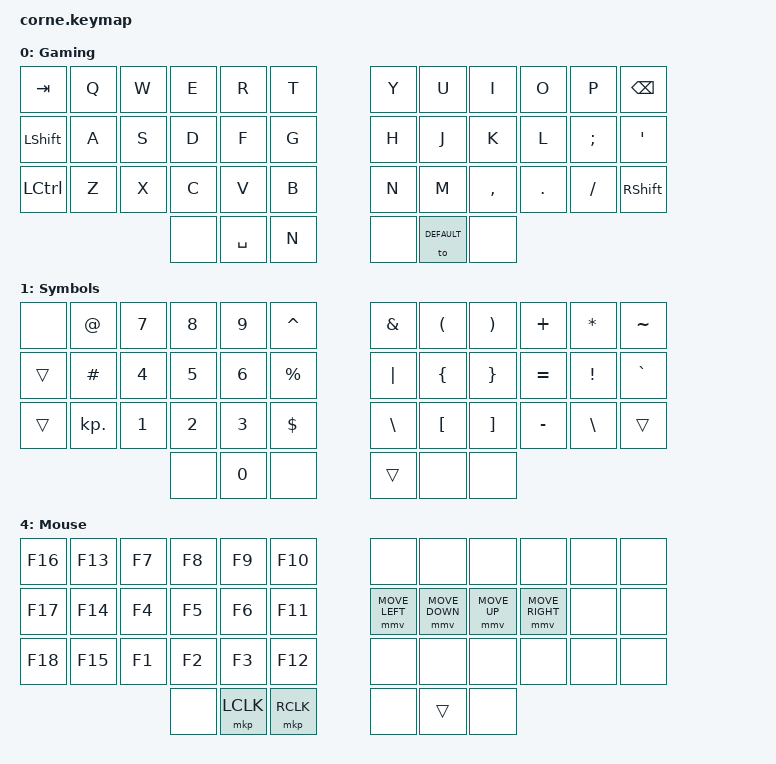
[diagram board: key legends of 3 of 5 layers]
#include <behaviors.dtsi>
#include <dt-bindings/zmk/bt.h>
#include <dt-bindings/zmk/keys.h>

#define DEFAULT 0
#define SYMBOLS 1
#define ACTIONS 2
#define CODING 3
#define MOUSE 4
#define GAMING 5

/ {
    /*
    behaviors {
        hm: homerow_mods {
            compatible = "zmk,behavior-hold-tap";
            label = "HOMEROW_MODS";
            #binding-cells = <2>;
            tapping-term-ms = <200>;
            quick_tap_ms = <0>;
            flavor = "tap-preferred";
            bindings = <&kp>, <&kp>;

            quick-tap-ms = <180>;
            global-quick-tap;
        };

        para: para {
            compatible = "zmk,behavior-tap-dance";
            label = "PARA";
            #binding-cells = <0>;
            bindings = <&kp LEFT_PARENTHESIS>, <&kp RIGHT_PARENTHESIS>;
        };

        caps: caps {
            compatible = "zmk,behavior-caps-word";
            label = "CAPS";
            #binding-cells = <0>;
            continue-list = <MINUS BACKSPACE>;
        };

        paraless: paraless {
            compatible = "zmk,behavior-mod-morph";
            label = "PARALESS";
            bindings = <&kp LEFT_PARENTHESIS>, <&kp LESS_THAN>;

            #binding-cells = <0>;
            mods = <(MOD_LSFT)>;
        };

        paragreat: paragreat {
            compatible = "zmk,behavior-mod-morph";
            label = "PARAGREAT";
            bindings = <&kp RIGHT_PARENTHESIS>, <&kp GREATER_THAN>;

            #binding-cells = <0>;
            mods = <(MOD_LSFT)>;
        };
    };

    macros {
        browsertab: browsertab {
            compatible = "zmk,behavior-macro";
            #binding-cells = <0>;
            bindings =
                <&macro_press>,
                <&kp LCTRL>,
                <&macro_tap>,
                <&kp TAB>,
                <&macro_release>,
                <&kp LCTRL>;
        };

    };

    combos {
        compatible = "zmk,combos";

        escape {
            bindings = <&kp ESCAPE>;
            key-positions = <13 29>;
        };

        delete {
            bindings = <&kp DELETE>;
            key-positions = <15 21>;
        };

        perc {
            bindings = <&kp PERCENT>;
            key-positions = <5 17>;
        };

        equal {
            bindings = <&kp EQUAL>;
            key-positions = <28 16>;
        };

        dollar {
            bindings = <&kp DOLLAR>;
            key-positions = <4 16>;
        };

        pound {
            bindings = <&kp POUND>;
            key-positions = <3 15>;
        };

        at {
            bindings = <&kp AT>;
            key-positions = <2 14>;
        };

        backslash {
            bindings = <&kp BACKSLASH>;
            key-positions = <26 14>;
        };

        copy {
            bindings = <&kp K_COPY>;
            key-positions = <28 27>;
        };

        paste {
            bindings = <&kp K_PASTE>;
            key-positions = <26 27>;
        };

        star {
            bindings = <&kp STAR>;
            key-positions = <8 20>;
        };

        slash {
            bindings = <&kp SLASH>;
            key-positions = <32 20>;
        };

        plus {
            bindings = <&kp PLUS>;
            key-positions = <7 19>;
        };

        minus {
            bindings = <&kp KP_MINUS>;
            key-positions = <31 19>;
        };

        underscore {
            bindings = <&kp UNDER>;
            key-positions = <30 18>;
        };

        leftbrack {
            bindings = <&kp LEFT_BRACKET>;
            key-positions = <31 32>;
        };

        rightbrack {
            bindings = <&kp RIGHT_BRACKET>;
            key-positions = <33 32>;
        };

        para-less {
            bindings = <&paraless>;
            key-positions = <20 19>;
        };

        para-great {
            bindings = <&paragreat>;
            key-positions = <20 21>;
        };
    };
    */

    keymap {
        compatible = "zmk,keymap";

        // -----------------------------------------------------------------------------------------

        DEFAULT {
            display-name = "Base";
            bindings = <
                &gresc         &kp Q       &kp W       &kp E        &kp R         &kp T    /*|*/    &kp Y  &kp U         &kp I        &kp O       &kp P          &kp BACKSPACE
                &mt LSHFT TAB  &mt LGUI A  &mt LALT S  &mt LCTRL D  &mt LSHIFT F  &kp G    /*|*/    &kp H  &mt RSHIFT J  &mt RCTRL K  &mt RALT L  &mt RGUI SEMI  &kp SQT
                &mo SYMBOLS    &kp Z       &kp X       &kp C        &kp V         &kp B    /*|*/    &kp N  &kp M         &kp COMMA    &kp DOT     &kp SLASH      &lt SYMBOLS MINUS
                                                        &kp LGUI  &mo ACTIONS  &mo CODING  /*|*/  &kp RET  &lt MOUSE SPACE  &kp LEFT_ALT
            >;
        };

        // -----------------------------------------------------------------------------------------

        SYMBOLS {
            display-name = "Symbols";
            bindings = <
                &none   &kp AT       &kp 7  &kp 8  &kp 9  &kp CARET    /*|*/    &kp AMPS       &kp LPAR  &kp RPAR  &kp PLUS   &kp STAR  &kp TILDE
                &trans  &kp HASH     &kp 4  &kp 5  &kp 6  &kp PERCENT  /*|*/    &kp PIPE       &kp LBRC  &kp RBRC  &kp EQUAL  &kp EXCL  &kp GRAVE
                &trans  &kp KP_DOT   &kp 1  &kp 2  &kp 3  &kp DOLLAR   /*|*/    &kp BACKSLASH  &kp LBKT  &kp RBKT  &kp MINUS  &kp BSLH  &trans
                                                  &none  &kp 0  &none  /*|*/  &trans  &none  &none
            >;
        };

        // -----------------------------------------------------------------------------------------

        ACTIONS {
            display-name = "Actions";
            bindings = <
                &kp C_VOL_UP  &kp C_PREV     &kp C_PP      &kp C_NEXT      &kp LALT SPACE  &kp LGUI DOT   /*|*/   &kp HOME              &kp PG_DN  &kp N8  &kp N9         &none  &kp DEL
                &kp C_MUTE    &kp LGUI       &kp LALT      &kp LCTRL       &kp LSHIFT      &to GAMING     /*|*/   &kp LEFT              &kp DOWN   &kp UP  &kp RIGHT      &none  &kp LGUI LSHIFT S
                &kp C_VOL_DN  &kp C_AC_UNDO  &kp C_AC_CUT  &kp C_AC_COPY   &kp C_AC_PASTE  &none          /*|*/   &kp LCTRL LSHIFT TAB  &none      &none   &kp LCTRL TAB  &none  &none
                                                                                   &none  &trans  &none   /*|*/      &none  &none  &none
            >;
        };

        // -----------------------------------------------------------------------------------------

        CODING {
            display-name = "Coding";
            bindings = <
                &none  &kp LSHFIT F11  &kp F11              &kp F10             &kp F2              &none                /*|*/   &none  &none  &none  &none  &none  &none
                &none  &kp LALT 0      &kp LALT LSHIFT F12  &kp LCTRL P         &kp LALT LSHIFT F   &kp F12              /*|*/   &none  &none  &none  &none  &none  &none
                &none  &none           &none                &kp LALT LSHIFT F8  &kp LALT F8         &kp LCTRL LSHIFT B   /*|*/   &none  &none  &none  &none  &none  &none
                                                                                                  &none  &none  &trans   /*|*/   &kp LCTRL DOT  &none  &none
            >;
        };

        // -----------------------------------------------------------------------------------------

        MOUSE {
            display-name = "Mouse";
            bindings = <
                &kp F16  &kp F13  &kp F7  &kp F8  &kp F9  &kp F10  /*|*/  &none  &none  &none  &none  &none  &none
                &kp F17  &kp F14  &kp F4  &kp F5  &kp F6  &kp F11  /*|*/  &mmv MOVE_LEFT  &mmv MOVE_DOWN  &mmv MOVE_UP  &mmv MOVE_RIGHT  &none  &none
                &kp F18  &kp F15  &kp F1  &kp F2  &kp F3  &kp F12  /*|*/  &none  &none  &none  &none  &none  &none
                                      &none  &mkp LCLK  &mkp RCLK  /*|*/  &none  &trans  &none
            >;
        };

        // -----------------------------------------------------------------------------------------

        DEFAULT {
            display-name = "Gaming";
            bindings = <
&kp TAB    &kp Q  &kp W  &kp E     &kp R  &kp T        &kp Y    &kp U      &kp I          &kp O    &kp P     &kp BACKSPACE
&kp LSHFT  &kp A  &kp S  &kp D     &kp F  &kp G        &kp H    &kp J      &kp K          &kp L    &kp SEMI  &kp SQT
&kp LCTRL  &kp Z  &kp X  &kp C     &kp V  &kp B        &kp N    &kp M      &kp COMMA      &kp DOT  &kp FSLH  &kp RSHFT
                         &none  &kp SPACE  &kp N    &none  &to DEFAULT  &none
            >;
        };
    };

    /*
    conditional_layers {
        compatible = "zmk,conditional-layers";

        l3 {
            if-layers = <1 2>;
            then-layer = <3>;
        };
    };
    */
}
